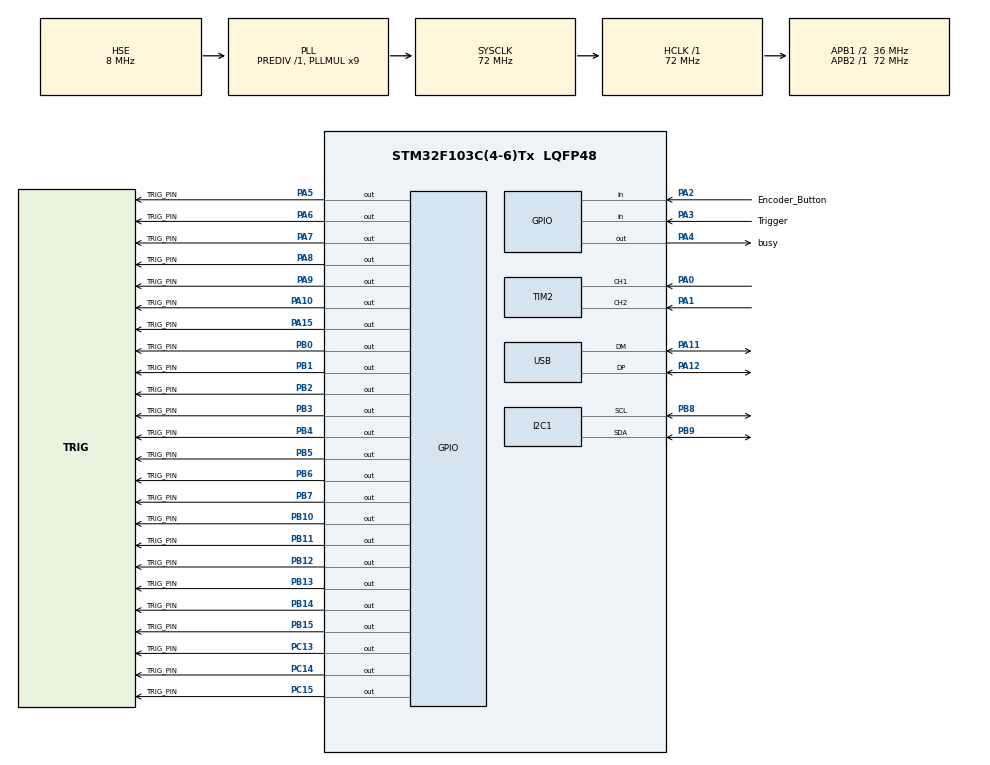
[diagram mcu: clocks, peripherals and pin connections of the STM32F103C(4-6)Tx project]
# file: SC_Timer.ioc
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Mcu.Family=STM32F1
Mcu.Name=STM32F103C(4-6)Tx
Mcu.Package=LQFP48
NVIC.PriorityGroup=NVIC_PRIORITYGROUP_4
NVIC.TIM1_UP_IRQn=true\:0\:0\:false\:false\:true\:true\:true
NVIC.USB_LP_CAN1_RX0_IRQn=true\:0\:0\:false\:false\:true\:false\:true
PA0-WKUP.GPIO_PuPd=GPIO_PULLDOWN
PA0-WKUP.Signal=S_TIM2_CH1_ETR
PA1.GPIO_PuPd=GPIO_PULLDOWN
PA1.Signal=S_TIM2_CH2
PA10.GPIO_Label=TRIG_PIN
PA10.GPIO_ModeDefaultOutputPP=GPIO_MODE_OUTPUT_PP
PA10.GPIO_PuPd=GPIO_PULLDOWN
PA10.GPIO_Speed=GPIO_SPEED_FREQ_HIGH
PA10.PinState=GPIO_PIN_SET
PA10.Signal=GPIO_Output
PA11.Mode=Device
PA11.Signal=USB_DM
PA12.Mode=Device
PA12.Signal=USB_DP
PA13.Mode=Serial_Wire
PA13.Signal=SYS_JTMS-SWDIO
PA14.Mode=Serial_Wire
PA14.Signal=SYS_JTCK-SWCLK
PA15.GPIO_Label=TRIG_PIN
PA15.GPIO_ModeDefaultOutputPP=GPIO_MODE_OUTPUT_PP
PA15.GPIO_PuPd=GPIO_PULLDOWN
PA15.GPIO_Speed=GPIO_SPEED_FREQ_HIGH
PA15.PinState=GPIO_PIN_SET
PA15.Signal=GPIO_Output
PA2.GPIO_Label=Encoder_Button
PA2.GPIO_PuPd=GPIO_PULLDOWN
PA2.Signal=GPIO_Input
PA3.GPIO_Label=Trigger
PA3.GPIO_PuPd=GPIO_PULLUP
PA3.Signal=GPIO_Input
PA4.GPIO_Label=busy
PA4.GPIO_PuPd=GPIO_PULLUP
PA4.Signal=GPIO_Output
PA5.GPIO_Label=TRIG_PIN
PA5.GPIO_PuPd=GPIO_PULLDOWN
PA5.GPIO_Speed=GPIO_SPEED_FREQ_HIGH
PA5.PinState=GPIO_PIN_SET
PA5.Signal=GPIO_Output
PA6.GPIO_Label=TRIG_PIN
PA6.GPIO_ModeDefaultOutputPP=GPIO_MODE_OUTPUT_PP
PA6.GPIO_PuPd=GPIO_PULLDOWN
PA6.GPIO_Speed=GPIO_SPEED_FREQ_HIGH
PA6.PinState=GPIO_PIN_SET
PA6.Signal=GPIO_Output
PA7.GPIO_Label=TRIG_PIN
PA7.GPIO_PuPd=GPIO_PULLDOWN
PA7.GPIO_Speed=GPIO_SPEED_FREQ_HIGH
PA7.PinState=GPIO_PIN_SET
PA7.Signal=GPIO_Output
PA8.GPIO_Label=TRIG_PIN
PA8.GPIO_ModeDefaultOutputPP=GPIO_MODE_OUTPUT_PP
PA8.GPIO_PuPd=GPIO_PULLDOWN
PA8.GPIO_Speed=GPIO_SPEED_FREQ_HIGH
PA8.PinState=GPIO_PIN_SET
PA8.Signal=GPIO_Output
PA9.GPIO_Label=TRIG_PIN
PA9.GPIO_ModeDefaultOutputPP=GPIO_MODE_OUTPUT_PP
PA9.GPIO_PuPd=GPIO_PULLDOWN
PA9.GPIO_Speed=GPIO_SPEED_FREQ_HIGH
PA9.PinState=GPIO_PIN_SET
PA9.Signal=GPIO_Output
PB0.GPIO_Label=TRIG_PIN
PB0.GPIO_ModeDefaultOutputPP=GPIO_MODE_OUTPUT_PP
PB0.GPIO_PuPd=GPIO_PULLDOWN
PB0.GPIO_Speed=GPIO_SPEED_FREQ_HIGH
PB0.PinState=GPIO_PIN_SET
PB0.Signal=GPIO_Output
PB1.GPIO_Label=TRIG_PIN
PB1.GPIO_ModeDefaultOutputPP=GPIO_MODE_OUTPUT_PP
PB1.GPIO_PuPd=GPIO_PULLDOWN
PB1.GPIO_Speed=GPIO_SPEED_FREQ_HIGH
PB1.PinState=GPIO_PIN_SET
PB1.Signal=GPIO_Output
PB10.GPIO_Label=TRIG_PIN
PB10.GPIO_ModeDefaultOutputPP=GPIO_MODE_OUTPUT_PP
PB10.GPIO_PuPd=GPIO_PULLDOWN
PB10.GPIO_Speed=GPIO_SPEED_FREQ_HIGH
PB10.PinState=GPIO_PIN_SET
PB10.Signal=GPIO_Output
PB11.GPIO_Label=TRIG_PIN
PB11.GPIO_ModeDefaultOutputPP=GPIO_MODE_OUTPUT_PP
PB11.GPIO_PuPd=GPIO_PULLDOWN
PB11.GPIO_Speed=GPIO_SPEED_FREQ_HIGH
PB11.PinState=GPIO_PIN_SET
PB11.Signal=GPIO_Output
PB12.GPIO_Label=TRIG_PIN
PB12.GPIO_ModeDefaultOutputPP=GPIO_MODE_OUTPUT_PP
PB12.GPIO_PuPd=GPIO_PULLDOWN
PB12.GPIO_Speed=GPIO_SPEED_FREQ_HIGH
PB12.PinState=GPIO_PIN_SET
PB12.Signal=GPIO_Output
PB13.GPIO_Label=TRIG_PIN
PB13.GPIO_ModeDefaultOutputPP=GPIO_MODE_OUTPUT_PP
PB13.GPIO_PuPd=GPIO_PULLDOWN
PB13.GPIO_Speed=GPIO_SPEED_FREQ_HIGH
PB13.PinState=GPIO_PIN_SET
PB13.Signal=GPIO_Output
PB14.GPIO_Label=TRIG_PIN
PB14.GPIO_ModeDefaultOutputPP=GPIO_MODE_OUTPUT_PP
PB14.GPIO_PuPd=GPIO_PULLDOWN
PB14.GPIO_Speed=GPIO_SPEED_FREQ_HIGH
PB14.PinState=GPIO_PIN_SET
PB14.Signal=GPIO_Output
PB15.GPIO_Label=TRIG_PIN
PB15.GPIO_ModeDefaultOutputPP=GPIO_MODE_OUTPUT_PP
PB15.GPIO_PuPd=GPIO_PULLDOWN
PB15.GPIO_Speed=GPIO_SPEED_FREQ_HIGH
PB15.PinState=GPIO_PIN_SET
PB15.Signal=GPIO_Output
PB2.GPIO_Label=TRIG_PIN
PB2.GPIO_ModeDefaultOutputPP=GPIO_MODE_OUTPUT_PP
PB2.GPIO_PuPd=GPIO_PULLDOWN
PB2.GPIO_Speed=GPIO_SPEED_FREQ_HIGH
PB2.PinState=GPIO_PIN_SET
PB2.Signal=GPIO_Output
PB3.GPIO_Label=TRIG_PIN
PB3.GPIO_ModeDefaultOutputPP=GPIO_MODE_OUTPUT_PP
PB3.GPIO_PuPd=GPIO_PULLDOWN
PB3.GPIO_Speed=GPIO_SPEED_FREQ_HIGH
PB3.PinState=GPIO_PIN_SET
PB3.Signal=GPIO_Output
PB4.GPIO_Label=TRIG_PIN
PB4.GPIO_ModeDefaultOutputPP=GPIO_MODE_OUTPUT_PP
PB4.GPIO_PuPd=GPIO_PULLDOWN
PB4.GPIO_Speed=GPIO_SPEED_FREQ_HIGH
PB4.PinState=GPIO_PIN_SET
PB4.Signal=GPIO_Output
PB5.GPIO_Label=TRIG_PIN
PB5.GPIO_ModeDefaultOutputPP=GPIO_MODE_OUTPUT_PP
PB5.GPIO_PuPd=GPIO_PULLDOWN
PB5.GPIO_Speed=GPIO_SPEED_FREQ_HIGH
PB5.PinState=GPIO_PIN_SET
PB5.Signal=GPIO_Output
PB6.GPIO_Label=TRIG_PIN
PB6.GPIO_ModeDefaultOutputPP=GPIO_MODE_OUTPUT_PP
PB6.GPIO_PuPd=GPIO_PULLDOWN
PB6.GPIO_Speed=GPIO_SPEED_FREQ_HIGH
PB6.PinState=GPIO_PIN_SET
PB6.Signal=GPIO_Output
PB7.GPIO_Label=TRIG_PIN
PB7.GPIO_ModeDefaultOutputPP=GPIO_MODE_OUTPUT_PP
PB7.GPIO_PuPd=GPIO_PULLDOWN
PB7.GPIO_Speed=GPIO_SPEED_FREQ_HIGH
PB7.PinState=GPIO_PIN_SET
PB7.Signal=GPIO_Output
PB8.Mode=I2C
PB8.Signal=I2C1_SCL
PB9.Mode=I2C
PB9.Signal=I2C1_SDA
PC13-TAMPER-RTC.GPIO_Label=TRIG_PIN
PC13-TAMPER-RTC.GPIO_ModeDefaultOutputPP=GPIO_MODE_OUTPUT_PP
PC13-TAMPER-RTC.GPIO_PuPd=GPIO_PULLDOWN
PC13-TAMPER-RTC.GPIO_Speed=GPIO_SPEED_FREQ_HIGH
PC13-TAMPER-RTC.PinState=GPIO_PIN_SET
PC13-TAMPER-RTC.Signal=GPIO_Output
PC14-OSC32_IN.GPIO_Label=TRIG_PIN
PC14-OSC32_IN.GPIO_ModeDefaultOutputPP=GPIO_MODE_OUTPUT_PP
PC14-OSC32_IN.GPIO_PuPd=GPIO_PULLDOWN
PC14-OSC32_IN.GPIO_Speed=GPIO_SPEED_FREQ_HIGH
PC14-OSC32_IN.PinState=GPIO_PIN_SET
PC14-OSC32_IN.Signal=GPIO_Output
PC15-OSC32_OUT.GPIO_Label=TRIG_PIN
PC15-OSC32_OUT.GPIO_ModeDefaultOutputPP=GPIO_MODE_OUTPUT_PP
PC15-OSC32_OUT.GPIO_PuPd=GPIO_PULLDOWN
PC15-OSC32_OUT.GPIO_Speed=GPIO_SPEED_FREQ_HIGH
PC15-OSC32_OUT.PinState=GPIO_PIN_SET
PC15-OSC32_OUT.Signal=GPIO_Output
PD0-OSC_IN.Mode=HSE-External-Oscillator
PD0-OSC_IN.Signal=RCC_OSC_IN
PD1-OSC_OUT.Mode=HSE-External-Oscillator
PD1-OSC_OUT.Signal=RCC_OSC_OUT
ProjectManager.HeapSize=0x200
ProjectManager.StackSize=0x400
ProjectManager.TargetToolchain=SW4STM32
RCC.AHBFreq_Value=72000000
RCC.APB1CLKDivider=RCC_HCLK_DIV2
RCC.APB1Freq_Value=36000000
RCC.APB1TimFreq_Value=72000000
RCC.APB2Freq_Value=72000000
RCC.APB2TimFreq_Value=72000000
RCC.HCLKFreq_Value=72000000
RCC.PLLMUL=RCC_PLL_MUL9
RCC.SYSCLKFreq_VALUE=72000000
RCC.SYSCLKSource=RCC_SYSCLKSOURCE_PLLCLK
RCC.USBFreq_Value=48000000
RCC.USBPrescaler=RCC_USBCLKSOURCE_PLL_DIV1_5
SH.S_TIM2_CH1_ETR.0=TIM2_CH1,Encoder_Interface
SH.S_TIM2_CH2.0=TIM2_CH2,Encoder_Interface
TIM1.AutoReloadPreload=TIM_AUTORELOAD_PRELOAD_ENABLE
TIM1.Period=71
TIM1.Prescaler=0
USB_DEVICE.CLASS_NAME_FS=CDC
USB_DEVICE.VirtualMode=Cdc
USB_DEVICE.VirtualModeFS=Cdc_FS
VP_TIM1_VS_ClockSourceINT.Mode=Internal
VP_USB_DEVICE_VS_USB_DEVICE_CDC_FS.Mode=CDC_FS
board=custom

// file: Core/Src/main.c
/* USER CODE BEGIN Header */
/**
  ******************************************************************************
  * @file           : main.c
  * @brief          : Main program body
  ******************************************************************************
  * @attention
  *
  * Copyright (c) 2022 STMicroelectronics.
  * All rights reserved.
  *
  * This software is licensed under terms that can be found in the LICENSE file
  * in the root directory of this software component.
  * If no LICENSE file comes with this software, it is provided AS-IS.
  *
  ******************************************************************************
  */
/* USER CODE END Header */
#include "main.h"
#include "usb_device.h"

/* USER CODE BEGIN Includes */
#include "SC_Timer_Core.h"
#include "usbd_cdc_if.h"
#include "stdio.h"
/* USER CODE END Includes */

I2C_HandleTypeDef hi2c1;

TIM_HandleTypeDef htim1;
TIM_HandleTypeDef htim2;

void SystemClock_Config(void);
static void MX_GPIO_Init(void);
static void MX_TIM1_Init(void);
static void MX_TIM2_Init(void);
static void MX_I2C1_Init(void);

int main(void)
{

  /* MCU Configuration--------------------------------------------------------*/

  /* Reset of all peripherals, Initializes the Flash interface and the Systick. */
  HAL_Init();

  /* Configure the system clock */
  SystemClock_Config();

  /* Initialize all configured peripherals */
  MX_GPIO_Init();
  MX_TIM1_Init();
  MX_USB_DEVICE_Init();
  MX_TIM2_Init();
  MX_I2C1_Init();
  /* USER CODE BEGIN 2 */
    main_setup();

  /* USER CODE END 2 */

  /* Infinite loop */
  /* USER CODE BEGIN WHILE */
  while (1)
  {
      main_loop();
      //HAL_GPIO_TogglePin(GPIOA, GPIO_PIN_4);
      //HAL_Delay(500);
    /* USER CODE END WHILE */

  }
}

void SystemClock_Config(void)
{
  RCC_OscInitTypeDef RCC_OscInitStruct = {0};
  RCC_ClkInitTypeDef RCC_ClkInitStruct = {0};
  RCC_PeriphCLKInitTypeDef PeriphClkInit = {0};

  /** Initializes the RCC Oscillators according to the specified parameters
  * in the RCC_OscInitTypeDef structure.
  */
  RCC_OscInitStruct.OscillatorType = RCC_OSCILLATORTYPE_HSE;
  RCC_OscInitStruct.HSEState = RCC_HSE_ON;
  RCC_OscInitStruct.HSEPredivValue = RCC_HSE_PREDIV_DIV1;
  RCC_OscInitStruct.HSIState = RCC_HSI_ON;
  RCC_OscInitStruct.PLL.PLLState = RCC_PLL_ON;
  RCC_OscInitStruct.PLL.PLLSource = RCC_PLLSOURCE_HSE;
  RCC_OscInitStruct.PLL.PLLMUL = RCC_PLL_MUL9;
  if (HAL_RCC_OscConfig(&RCC_OscInitStruct) != HAL_OK)
  {
    Error_Handler();
  }
  /** Initializes the CPU, AHB and APB buses clocks
  */
  RCC_ClkInitStruct.ClockType = RCC_CLOCKTYPE_HCLK|RCC_CLOCKTYPE_SYSCLK
                              |RCC_CLOCKTYPE_PCLK1|RCC_CLOCKTYPE_PCLK2;
  RCC_ClkInitStruct.SYSCLKSource = RCC_SYSCLKSOURCE_PLLCLK;
  RCC_ClkInitStruct.AHBCLKDivider = RCC_SYSCLK_DIV1;
  RCC_ClkInitStruct.APB1CLKDivider = RCC_HCLK_DIV2;
  RCC_ClkInitStruct.APB2CLKDivider = RCC_HCLK_DIV1;

  if (HAL_RCC_ClockConfig(&RCC_ClkInitStruct, FLASH_LATENCY_2) != HAL_OK)
  {
    Error_Handler();
  }
  PeriphClkInit.PeriphClockSelection = RCC_PERIPHCLK_USB;
  PeriphClkInit.UsbClockSelection = RCC_USBCLKSOURCE_PLL_DIV1_5;
  if (HAL_RCCEx_PeriphCLKConfig(&PeriphClkInit) != HAL_OK)
  {
    Error_Handler();
  }
}

static void MX_I2C1_Init(void)
{

  hi2c1.Instance = I2C1;
  hi2c1.Init.ClockSpeed = 100000;
  hi2c1.Init.DutyCycle = I2C_DUTYCYCLE_2;
  hi2c1.Init.OwnAddress1 = 0;
  hi2c1.Init.AddressingMode = I2C_ADDRESSINGMODE_7BIT;
  hi2c1.Init.DualAddressMode = I2C_DUALADDRESS_DISABLE;
  hi2c1.Init.OwnAddress2 = 0;
  hi2c1.Init.GeneralCallMode = I2C_GENERALCALL_DISABLE;
  hi2c1.Init.NoStretchMode = I2C_NOSTRETCH_DISABLE;
  if (HAL_I2C_Init(&hi2c1) != HAL_OK)
  {
    Error_Handler();
  }

}

static void MX_TIM1_Init(void)
{

  TIM_ClockConfigTypeDef sClockSourceConfig = {0};
  TIM_MasterConfigTypeDef sMasterConfig = {0};

  htim1.Instance = TIM1;
  htim1.Init.Prescaler = 0;
  htim1.Init.CounterMode = TIM_COUNTERMODE_UP;
  htim1.Init.Period = 71;
  htim1.Init.ClockDivision = TIM_CLOCKDIVISION_DIV1;
  htim1.Init.RepetitionCounter = 0;
  htim1.Init.AutoReloadPreload = TIM_AUTORELOAD_PRELOAD_ENABLE;
  if (HAL_TIM_Base_Init(&htim1) != HAL_OK)
  {
    Error_Handler();
  }
  sClockSourceConfig.ClockSource = TIM_CLOCKSOURCE_INTERNAL;
  if (HAL_TIM_ConfigClockSource(&htim1, &sClockSourceConfig) != HAL_OK)
  {
    Error_Handler();
  }
  sMasterConfig.MasterOutputTrigger = TIM_TRGO_RESET;
  sMasterConfig.MasterSlaveMode = TIM_MASTERSLAVEMODE_DISABLE;
  if (HAL_TIMEx_MasterConfigSynchronization(&htim1, &sMasterConfig) != HAL_OK)
  {
    Error_Handler();
  }

}

static void MX_TIM2_Init(void)
{

  TIM_Encoder_InitTypeDef sConfig = {0};
  TIM_MasterConfigTypeDef sMasterConfig = {0};

  htim2.Instance = TIM2;
  htim2.Init.Prescaler = 0;
  htim2.Init.CounterMode = TIM_COUNTERMODE_UP;
  htim2.Init.Period = 65535;
  htim2.Init.ClockDivision = TIM_CLOCKDIVISION_DIV1;
  htim2.Init.AutoReloadPreload = TIM_AUTORELOAD_PRELOAD_DISABLE;
  sConfig.EncoderMode = TIM_ENCODERMODE_TI1;
  sConfig.IC1Polarity = TIM_ICPOLARITY_RISING;
  sConfig.IC1Selection = TIM_ICSELECTION_DIRECTTI;
  sConfig.IC1Prescaler = TIM_ICPSC_DIV1;
  sConfig.IC1Filter = 0;
  sConfig.IC2Polarity = TIM_ICPOLARITY_RISING;
  sConfig.IC2Selection = TIM_ICSELECTION_DIRECTTI;
  sConfig.IC2Prescaler = TIM_ICPSC_DIV1;
  sConfig.IC2Filter = 0;
  if (HAL_TIM_Encoder_Init(&htim2, &sConfig) != HAL_OK)
  {
    Error_Handler();
  }
  sMasterConfig.MasterOutputTrigger = TIM_TRGO_RESET;
  sMasterConfig.MasterSlaveMode = TIM_MASTERSLAVEMODE_DISABLE;
  if (HAL_TIMEx_MasterConfigSynchronization(&htim2, &sMasterConfig) != HAL_OK)
  {
    Error_Handler();
  }

}

static void MX_GPIO_Init(void)
{
  GPIO_InitTypeDef GPIO_InitStruct = {0};

  /* GPIO Ports Clock Enable */
  __HAL_RCC_GPIOC_CLK_ENABLE();
  __HAL_RCC_GPIOD_CLK_ENABLE();
  __HAL_RCC_GPIOA_CLK_ENABLE();
  __HAL_RCC_GPIOB_CLK_ENABLE();

  /*Configure GPIO pin Output Level */
  HAL_GPIO_WritePin(GPIOC, GPIO_PIN_13|GPIO_PIN_14|GPIO_PIN_15, GPIO_PIN_SET);

  /*Configure GPIO pin Output Level */
  HAL_GPIO_WritePin(busy_GPIO_Port, busy_Pin, GPIO_PIN_RESET);

  /*Configure GPIO pin Output Level */
  HAL_GPIO_WritePin(GPIOA, GPIO_PIN_5|GPIO_PIN_6|GPIO_PIN_7|GPIO_PIN_8
                          |GPIO_PIN_9|GPIO_PIN_10|GPIO_PIN_15, GPIO_PIN_SET);

  /*Configure GPIO pin Output Level */
  HAL_GPIO_WritePin(GPIOB, GPIO_PIN_0|GPIO_PIN_1|GPIO_PIN_2|GPIO_PIN_10
                          |GPIO_PIN_11|GPIO_PIN_12|GPIO_PIN_13|GPIO_PIN_14
                          |GPIO_PIN_15|GPIO_PIN_3|GPIO_PIN_4|GPIO_PIN_5
                          |GPIO_PIN_6|TRIG_PIN_Pin, GPIO_PIN_SET);

  /*Configure GPIO pins : PC13 PC14 PC15 */
  GPIO_InitStruct.Pin = GPIO_PIN_13|GPIO_PIN_14|GPIO_PIN_15;
  GPIO_InitStruct.Mode = GPIO_MODE_OUTPUT_PP;
  GPIO_InitStruct.Pull = GPIO_PULLDOWN;
  GPIO_InitStruct.Speed = GPIO_SPEED_FREQ_HIGH;
  HAL_GPIO_Init(GPIOC, &GPIO_InitStruct);

  /*Configure GPIO pin : Encoder_Button_Pin */
  GPIO_InitStruct.Pin = Encoder_Button_Pin;
  GPIO_InitStruct.Mode = GPIO_MODE_INPUT;
  GPIO_InitStruct.Pull = GPIO_PULLDOWN;
  HAL_GPIO_Init(Encoder_Button_GPIO_Port, &GPIO_InitStruct);

  /*Configure GPIO pin : Trigger_Pin */
  GPIO_InitStruct.Pin = Trigger_Pin;
  GPIO_InitStruct.Mode = GPIO_MODE_INPUT;
  GPIO_InitStruct.Pull = GPIO_PULLUP;
  HAL_GPIO_Init(Trigger_GPIO_Port, &GPIO_InitStruct);

  /*Configure GPIO pin : busy_Pin */
  GPIO_InitStruct.Pin = busy_Pin;
  GPIO_InitStruct.Mode = GPIO_MODE_OUTPUT_PP;
  GPIO_InitStruct.Pull = GPIO_PULLUP;
  GPIO_InitStruct.Speed = GPIO_SPEED_FREQ_LOW;
  HAL_GPIO_Init(busy_GPIO_Port, &GPIO_InitStruct);

  /*Configure GPIO pins : PA5 PA6 PA7 PA8
                           PA9 PA10 PA15 */
  GPIO_InitStruct.Pin = GPIO_PIN_5|GPIO_PIN_6|GPIO_PIN_7|GPIO_PIN_8
                          |GPIO_PIN_9|GPIO_PIN_10|GPIO_PIN_15;
  GPIO_InitStruct.Mode = GPIO_MODE_OUTPUT_PP;
  GPIO_InitStruct.Pull = GPIO_PULLDOWN;
  GPIO_InitStruct.Speed = GPIO_SPEED_FREQ_HIGH;
  HAL_GPIO_Init(GPIOA, &GPIO_InitStruct);

  /*Configure GPIO pins : PB0 PB1 PB2 PB10
                           PB11 PB12 PB13 PB14
                           PB15 PB3 PB4 PB5
                           PB6 TRIG_PIN_Pin */
  GPIO_InitStruct.Pin = GPIO_PIN_0|GPIO_PIN_1|GPIO_PIN_2|GPIO_PIN_10
                          |GPIO_PIN_11|GPIO_PIN_12|GPIO_PIN_13|GPIO_PIN_14
                          |GPIO_PIN_15|GPIO_PIN_3|GPIO_PIN_4|GPIO_PIN_5
                          |GPIO_PIN_6|TRIG_PIN_Pin;
  GPIO_InitStruct.Mode = GPIO_MODE_OUTPUT_PP;
  GPIO_InitStruct.Pull = GPIO_PULLDOWN;
  GPIO_InitStruct.Speed = GPIO_SPEED_FREQ_HIGH;
  HAL_GPIO_Init(GPIOB, &GPIO_InitStruct);

}

void Error_Handler(void)
{
  __disable_irq();
  while (1)
  {
  }
}
